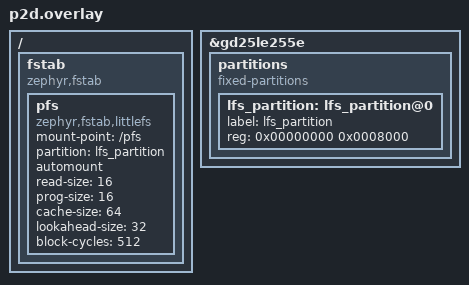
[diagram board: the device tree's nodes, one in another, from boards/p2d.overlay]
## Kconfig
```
# Copyright (c) 2021 Nordic Semiconductor ASA
# SPDX-License-Identifier: Apache-2.0
#
# This file is the application Kconfig entry point. All application Kconfig
# options can be defined here or included via other application Kconfig files.
# You can browse these options using the west targets menuconfig (terminal) or
# guiconfig (GUI).

menu "Zephyr"
source "Kconfig.zephyr"

config KERNEL_MAIN_STACK_SIZE
  int "Stack size for PebbleOS main kernel thread."
  default 2048

config KERNEL_MAIN_PRIORITY
  int "Priority for PebbleOS main kernel thread."
  default 5

config KERNEL_BACKGROUND_STACK_SIZE
  int "Stack size for PebbleOS background kernel thread."
  default 2048

config KERNEL_BACKGROUND_PRIORITY
  int "Priority for PebbleOS background kernel thread."
  default 5
endmenu

config MAX_KERNEL_EVENTS
  int "Maximum kernel events."
  default 32

config MAX_FROM_APP_EVENTS
  int "Maximum events from an app."
  default 10

config MAX_FROM_WORKER_EVENTS
  int "Maximum events from a worker."
  default 5

config MAX_FROM_KERNEL_MAIN_EVENTS
  int "Maximum events from main kernel."
  default 14

config EVENT_QUEUE_PUT_TIMEOUT_MS
  int "Maximum time to block until event is put into queue."
  default 3000

config MAIN_EVENT_LOOP_TAKE_TIMEOUT_MS
  int "Maximum time to block waiting for event."
  default 1000

config MFG_SERIAL_NUMBER_SIZE
  int "Size of serial number not including NULL terminator"
  default 12

module = APP
module-str = APP
```

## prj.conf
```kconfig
# Copyright (c) 2021 Nordic Semiconductor ASA
# SPDX-License-Identifier: Apache-2.0
#
# This file contains selected Kconfig options for the application.

# Logging
CONFIG_LOG=y
CONFIG_PRINTK=y
CONFIG_SERIAL=y
CONFIG_CONSOLE=y
CONFIG_UART_CONSOLE=y
CONFIG_LOG_BACKEND_UART=y

# Assert
CONFIG_ASSERT=y
CONFIG_ASSERT_VERBOSE=y

# Compile Options
CONFIG_DEBUG=y

# Reboot
CONFIG_REBOOT=y

# Shell
CONFIG_SHELL=y
CONFIG_SHELL_LOG_BACKEND=n
CONFIG_REGULATOR_SHELL=y
CONFIG_SENSOR_SHELL=y

# MPU & Stack Protection
CONFIG_ARM_MPU=y
CONFIG_HW_STACK_PROTECTION=y

# Stack Sizes
CONFIG_MAIN_STACK_SIZE=4096
CONFIG_SYSTEM_WORKQUEUE_STACK_SIZE=4096
CONFIG_BT_RX_STACK_SIZE=2048

# Regulator
CONFIG_REGULATOR=y

# Heap
CONFIG_THREAD_CUSTOM_DATA=y
CONFIG_DYNAMIC_THREAD=y
CONFIG_DYNAMIC_THREAD_ALLOC=y
CONFIG_DYNAMIC_THREAD_PREFER_ALLOC=y

CONFIG_POLL=y

# Flash
CONFIG_FLASH=y
CONFIG_FLASH_MAP=y
CONFIG_FLASH_SHELL=y

# Filesystem
CONFIG_FILE_SYSTEM=y
CONFIG_FILE_SYSTEM_LITTLEFS=y

# Settings
CONFIG_SETTINGS=y
CONFIG_SETTINGS_FILE=y
CONFIG_SETTINGS_FILE_PATH="/pfs/settings"

# Sensors
CONFIG_SENSOR=y

# BLE
CONFIG_BT=y
CONFIG_BT_PERIPHERAL=y
CONFIG_BT_DEVICE_NAME="Pebble 1234"
CONFIG_BT_GATT_CLIENT=y
CONFIG_BT_GATT_AUTO_DISCOVER_CCC=y

# BLE Additional Settings
CONFIG_BT_SMP=y
CONFIG_BT_BONDABLE=y

# Bluetooth settings
CONFIG_BT_SETTINGS=y

CONFIG_UUID=y
```

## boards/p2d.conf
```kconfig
# Flash
CONFIG_NORDIC_QSPI_NOR=y
CONFIG_NORDIC_QSPI_NOR_INIT_PRIORITY=90

# QSPI
CONFIG_SPI=y

# I2C
CONFIG_I2C=y

# Charging & Fuel Gauge
CONFIG_CHARGER=y
CONFIG_FUEL_GAUGE=y
CONFIG_FUEL_GAUGE_COMPOSITE=y
```

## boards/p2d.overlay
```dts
/ {
  fstab {
        compatible = "zephyr,fstab";
        pfs: pfs {
            compatible = "zephyr,fstab,littlefs";
            mount-point = "/pfs";
            partition = <&lfs_partition>;
            automount;
            read-size = <16>;
            prog-size = <16>;
            cache-size = <64>;
            lookahead-size = <32>;
            block-cycles = <512>;
        };
    };
};

&gd25le255e {
	partitions {
		compatible = "fixed-partitions";
		#address-cells = <1>;
		#size-cells = <1>;

		lfs_partition: lfs_partition@0 {
			label = "lfs_partition";
			reg = <0x00000000 0x0008000>;
		};
	};
};
```

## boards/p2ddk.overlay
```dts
/ {
  fstab {
        compatible = "zephyr,fstab";
        pfs: pfs {
            compatible = "zephyr,fstab,littlefs";
            mount-point = "/pfs";
            partition = <&lfs_partition>;
            automount;
            read-size = <16>;
            prog-size = <16>;
            cache-size = <64>;
            lookahead-size = <32>;
            block-cycles = <512>;
        };
    };
};

&mx25r64 {
	partitions {
		compatible = "fixed-partitions";
		#address-cells = <1>;
		#size-cells = <1>;

		lfs_partition: lfs_partition@0 {
			label = "lfs_partition";
			reg = <0x00000000 0x00010000>;
		};
	};
};
```

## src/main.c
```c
/*
 * Copyright (C) Evan Stoddard
 */

/**
 * @file main.c
 * @brief Zephyr application entry point. Initializes the kernel heap and
 * launches the kernel main thread.
 */

#include <zephyr/kernel.h>
#include <zephyr/logging/log.h>

#include "kernel/kernel_heap.h"

#include "kernel/kernel_main.h"

/*****************************************************************************
 * Definitions
 *****************************************************************************/

LOG_MODULE_REGISTER(main);

/*****************************************************************************
 * Variables
 *****************************************************************************/

/*****************************************************************************
 * Prototypes
 *****************************************************************************/

/*****************************************************************************
 * Functions
 *****************************************************************************/

int main(void) {
  LOG_INF("Booting PebbleOS.");

  // Initialize kernel heap
  kernel_heap_init();

  kernel_main_init();

  return 0;
}
```

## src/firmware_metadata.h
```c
/*
 * Copyright (C) Ovyl
 */

/**
 * @file firmware_metadata.h
 * @author Evan Stoddard
 * @brief
 */

#ifndef firmware_metadata_h
#define firmware_metadata_h

#ifdef __cplusplus
extern "C" {
#endif

/*****************************************************************************
 * Definitions
 *****************************************************************************/

/*****************************************************************************
 * Structs, Unions, Enums, & Typedefs
 *****************************************************************************/

typedef enum FirmwareMetadataPlatform {
  FirmwareMetadataPlatformUnknown = 0,
  FirmwareMetadataPlatformPebbleOneEV1 = 1,
  FirmwareMetadataPlatformPebbleOneEV2 = 2,
  FirmwareMetadataPlatformPebbleOneEV2_3 = 3,
  FirmwareMetadataPlatformPebbleOneEV2_4 = 4,
  FirmwareMetadataPlatformPebbleOnePointFive = 5,
  FirmwareMetadataPlatformPebbleTwoPointZero = 6,
  FirmwareMetadataPlatformPebbleSnowyEVT2 = 7,
  FirmwareMetadataPlatformPebbleSnowyDVT = 8,
  FirmwareMetadataPlatformPebbleSpaldingEVT = 9,
  FirmwareMetadataPlatformPebbleBobbyDVT = 10,
  FirmwareMetadataPlatformPebbleSpalding = 11,
  FirmwareMetadataPlatformPebbleSilkEVT = 12,
  FirmwareMetadataPlatformPebbleRobertEVT = 13,
  FirmwareMetadataPlatformPebbleSilk = 14,
  FirmwareMetadataPlatformPebbleAsterix = 15,
  FirmwareMetadataPlatformPebbleObelixEVT = 16,
  FirmwareMetadataPlatformPebbleObelixDVT = 17,
  FirmwareMetadataPlatformPebbleObelixPVT = 18,

  FirmwareMetadataPlatformPebbleOneBigboard = 0xff,
  FirmwareMetadataPlatformPebbleOneBigboard2 = 0xfe,
  FirmwareMetadataPlatformPebbleSnowyBigboard = 0xfd,
  FirmwareMetadataPlatformPebbleSnowyBigboard2 = 0xfc,
  FirmwareMetadataPlatformPebbleSpaldingBigboard = 0xfb,
  FirmwareMetadataPlatformPebbleSilkBigboard = 0xfa,
  FirmwareMetadataPlatformPebbleRobertBigboard = 0xf9,
  FirmwareMetadataPlatformPebbleSilkBigboard2 = 0xf8,
  FirmwareMetadataPlatformPebbleRobertBigboard2 = 0xf7,
  FirmwareMetadataPlatformPebbleSilkFlint = 0xf6,
  FirmwareMetadataPlatformPebbleSnowyEmery = 0xf5,
  FirmwareMetadataPlatformPebbleObelixBigboard = 0xf4,
  FirmwareMetadataPlatformPebbleObelixBigboard2 = 0xf3,
} FirmwareMetadataPlatform;

/*****************************************************************************
 * Function Prototypes
 *****************************************************************************/

#ifdef __cplusplus
}
#endif
#endif /* firmware_metadata_h */
```
